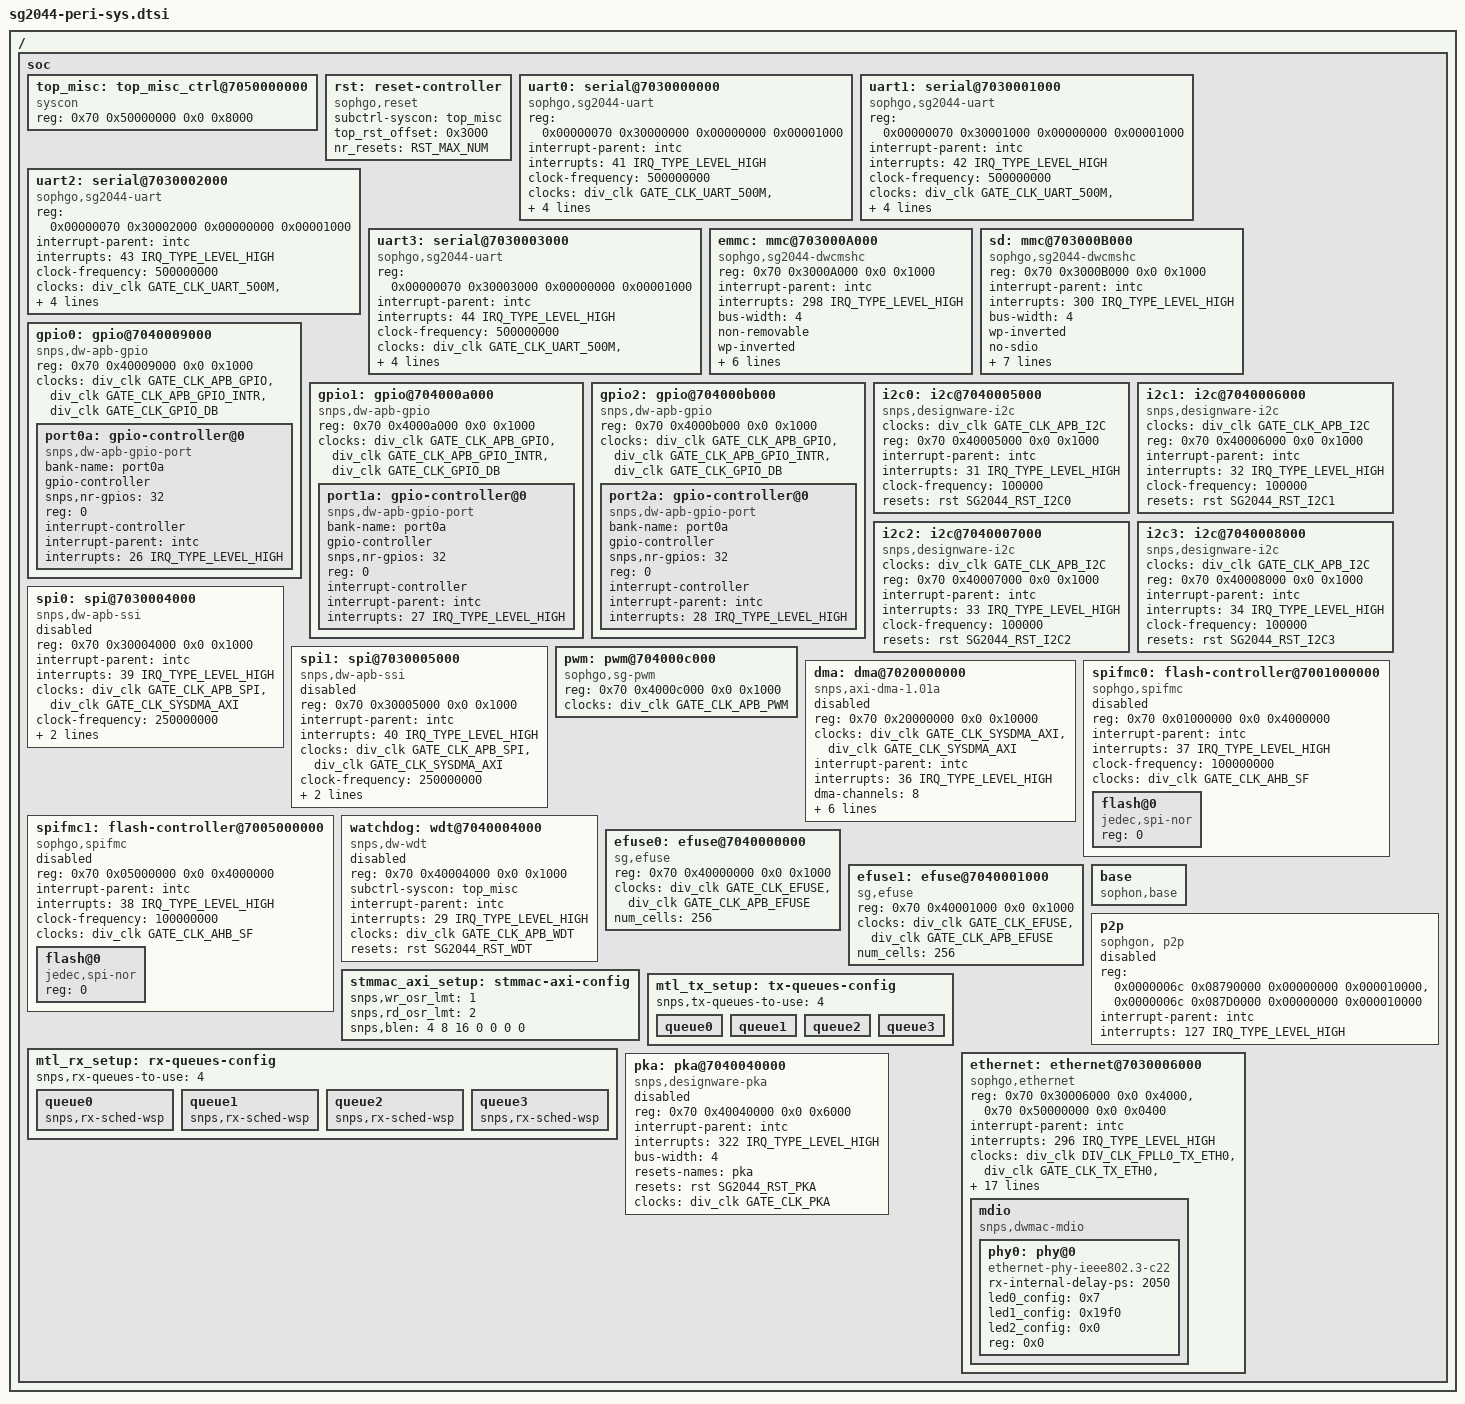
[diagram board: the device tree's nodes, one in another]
// SPDX-License-Identifier: (GPL-2.0 OR MIT)
/*
 * Copyright (C) 2022 Sophgo Technology Inc. All rights reserved.
 */

/ {
	soc {
		top_misc: top_misc_ctrl@7050000000 {
			compatible = "syscon";
			reg = <0x70 0x50000000 0x0 0x8000>;
		};

		rst: reset-controller {
			#reset-cells = <1>;
			compatible = "sophgo,reset";
			subctrl-syscon = <&top_misc>;
			top_rst_offset = <0x3000>;
			nr_resets = <RST_MAX_NUM>;
		};

		uart0: serial@7030000000 {
			compatible = "sophgo,sg2044-uart", "snps,dw-apb-uart";
			reg = <0x00000070 0x30000000 0x00000000 0x00001000>;
			interrupt-parent = <&intc>;
			interrupts = <41 IRQ_TYPE_LEVEL_HIGH>;
			clock-frequency = <500000000>;
			clocks = <&div_clk GATE_CLK_UART_500M>,
				<&div_clk GATE_CLK_APB_UART>;
			clock-names = "baudclk", "apb_pclk";
			current-speed = <115200>;
			reg-shift = <2>;
			reg-io-width = <4>;
		};

		uart1: serial@7030001000 {
			compatible = "sophgo,sg2044-uart", "snps,dw-apb-uart";
			reg = <0x00000070 0x30001000 0x00000000 0x00001000>;
			interrupt-parent = <&intc>;
			interrupts = <42 IRQ_TYPE_LEVEL_HIGH>;
			clock-frequency = <500000000>;
			clocks = <&div_clk GATE_CLK_UART_500M>,
				<&div_clk GATE_CLK_APB_UART>;
			clock-names = "baudclk", "apb_pclk";
			current-speed = <115200>;
			reg-shift = <2>;
			reg-io-width = <4>;
		};

		uart2: serial@7030002000 {
			compatible = "sophgo,sg2044-uart", "snps,dw-apb-uart";
			reg = <0x00000070 0x30002000 0x00000000 0x00001000>;
			interrupt-parent = <&intc>;
			interrupts = <43 IRQ_TYPE_LEVEL_HIGH>;
			clock-frequency = <500000000>;
			clocks = <&div_clk GATE_CLK_UART_500M>,
				<&div_clk GATE_CLK_APB_UART>;
			clock-names = "baudclk", "apb_pclk";
			current-speed = <115200>;
			reg-shift = <2>;
			reg-io-width = <4>;
		};

		uart3: serial@7030003000 {
			compatible = "sophgo,sg2044-uart", "snps,dw-apb-uart";
			reg = <0x00000070 0x30003000 0x00000000 0x00001000>;
			interrupt-parent = <&intc>;
			interrupts = <44 IRQ_TYPE_LEVEL_HIGH>;
			clock-frequency = <500000000>;
			clocks = <&div_clk GATE_CLK_UART_500M>,
				<&div_clk GATE_CLK_APB_UART>;
			clock-names = "baudclk", "apb_pclk";
			current-speed = <115200>;
			reg-shift = <2>;
			reg-io-width = <4>;
		};

		emmc: mmc@703000A000 {
			compatible = "sophgo,sg2044-dwcmshc", "sophgo,sg2042-dwcmshc";
			reg = <0x70 0x3000A000 0x0 0x1000>;
			reg-names = "core_mem";
			interrupt-parent = <&intc>;
			interrupts = <298 IRQ_TYPE_LEVEL_HIGH>;
			bus-width = <4>;
			non-removable;
			wp-inverted;
			no-sdio;
			no-sd;
			resets = <&rst SG2044_RST_EMMC>;
			reset-names = "emmc";
			clocks =
			<&div_clk GATE_CLK_EMMC>,
			<&div_clk GATE_CLK_AXI_EMMC>,
			<&div_clk GATE_CLK_100K_EMMC>;
			clock-names = "core", "bus", "timer";
		};

		sd: mmc@703000B000 {
			compatible = "sophgo,sg2044-dwcmshc", "sophgo,sg2042-dwcmshc";
			reg = <0x70 0x3000B000 0x0 0x1000>;
			reg-names = "core_mem";
			interrupt-parent = <&intc>;
			interrupts = <300 IRQ_TYPE_LEVEL_HIGH>;
			bus-width = <4>;
			wp-inverted;
			no-sdio;
			no-mmc;
			no-1-8-v;
			switch-voltage-gpio = <&port0a 27 0>;
			resets = <&rst SG2044_RST_SD>;
			reset-names = "sdio";
			clocks =
			<&div_clk GATE_CLK_SD>,
			<&div_clk GATE_CLK_AXI_SD>,
			<&div_clk GATE_CLK_100K_SD>;
			clock-names = "core", "bus", "timer";
		};

		gpio0: gpio@7040009000 {
			compatible = "snps,dw-apb-gpio";
			reg = <0x70 0x40009000 0x0 0x1000>;
			#address-cells = <1>;
			#size-cells = <0>;
			clocks = <&div_clk GATE_CLK_APB_GPIO>,
					<&div_clk GATE_CLK_APB_GPIO_INTR>,
					<&div_clk GATE_CLK_GPIO_DB>;
			clock-names = "base_clk", "intr_clk", "db_clk";

			port0a: gpio-controller@0 {
				compatible = "snps,dw-apb-gpio-port";
				bank-name = "port0a";
				gpio-controller;
				#gpio-cells = <2>;
				snps,nr-gpios = <32>;
				reg = <0>;
				interrupt-controller;
				#interrupt-cells = <2>;
				interrupt-parent = <&intc>;
				interrupts = <26 IRQ_TYPE_LEVEL_HIGH>;
			};
		};

		gpio1: gpio@704000a000 {
			compatible = "snps,dw-apb-gpio";
			reg = <0x70 0x4000a000 0x0 0x1000>;
			#address-cells = <1>;
			#size-cells = <0>;

			clocks = <&div_clk GATE_CLK_APB_GPIO>,
					<&div_clk GATE_CLK_APB_GPIO_INTR>,
					<&div_clk GATE_CLK_GPIO_DB>;
			clock-names = "base_clk", "intr_clk", "db_clk";

			port1a: gpio-controller@0 {
				compatible = "snps,dw-apb-gpio-port";
				bank-name = "port0a";
				gpio-controller;
				#gpio-cells = <2>;
				snps,nr-gpios = <32>;
				reg = <0>;
				interrupt-controller;
				#interrupt-cells = <2>;
				interrupt-parent = <&intc>;
				interrupts = <27 IRQ_TYPE_LEVEL_HIGH>;
			};
		};

		gpio2: gpio@704000b000 {
			compatible = "snps,dw-apb-gpio";
			reg = <0x70 0x4000b000 0x0 0x1000>;
			#address-cells = <1>;
			#size-cells = <0>;
			clocks = <&div_clk GATE_CLK_APB_GPIO>,
					<&div_clk GATE_CLK_APB_GPIO_INTR>,
					<&div_clk GATE_CLK_GPIO_DB>;
			clock-names = "base_clk", "intr_clk", "db_clk";

			port2a: gpio-controller@0 {
				compatible = "snps,dw-apb-gpio-port";
				bank-name = "port0a";
				gpio-controller;
				#gpio-cells = <2>;
				snps,nr-gpios = <32>;
				reg = <0>;
				interrupt-controller;
				#interrupt-cells = <2>;
				interrupt-parent = <&intc>;
				interrupts = <28 IRQ_TYPE_LEVEL_HIGH>;
			};
		};

		i2c0: i2c@7040005000 {
			#address-cells = <1>;
			#size-cells = <0>;
			compatible = "snps,designware-i2c";
			clocks = <&div_clk GATE_CLK_APB_I2C>;
			clock-names = "clk_gate_apb_i2c";
			reg = <0x70 0x40005000 0x0 0x1000>;
			interrupt-parent = <&intc>;
			interrupts = <31 IRQ_TYPE_LEVEL_HIGH>;
			clock-frequency = <100000>;
			resets = <&rst SG2044_RST_I2C0>;
			reset-names = "i2c0";
		};

		i2c1: i2c@7040006000 {
			#address-cells = <1>;
			#size-cells = <0>;
			compatible = "snps,designware-i2c";
			clocks = <&div_clk GATE_CLK_APB_I2C>;
			clock-names = "clk_gate_apb_i2c";
			reg = <0x70 0x40006000 0x0 0x1000>;
			interrupt-parent = <&intc>;
			interrupts = <32 IRQ_TYPE_LEVEL_HIGH>;
			clock-frequency = <100000>;
			resets = <&rst SG2044_RST_I2C1>;
			reset-names = "i2c1";
		};

		i2c2: i2c@7040007000 {
			#address-cells = <1>;
			#size-cells = <0>;
			compatible = "snps,designware-i2c";
			clocks = <&div_clk GATE_CLK_APB_I2C>;
			clock-names = "clk_gate_apb_i2c";
			reg = <0x70 0x40007000 0x0 0x1000>;
			interrupt-parent = <&intc>;
			interrupts = <33 IRQ_TYPE_LEVEL_HIGH>;
			clock-frequency = <100000>;
			resets = <&rst SG2044_RST_I2C2>;
			reset-names = "i2c2";
		};

		i2c3: i2c@7040008000 {
			#address-cells = <1>;
			#size-cells = <0>;
			compatible = "snps,designware-i2c";
			clocks = <&div_clk GATE_CLK_APB_I2C>;
			clock-names = "clk_gate_apb_i2c";
			reg = <0x70 0x40008000 0x0 0x1000>;
			interrupt-parent = <&intc>;
			interrupts = <34 IRQ_TYPE_LEVEL_HIGH>;
			clock-frequency = <100000>;
			resets = <&rst SG2044_RST_I2C3>;
			reset-names = "i2c3";
		};

		spi0: spi@7030004000 {
			compatible = "snps,dw-apb-ssi";
			#address-cells = <1>;
			#size-cells = <0>;
			reg = <0x70 0x30004000 0x0 0x1000>;
			interrupt-parent = <&intc>;
			interrupts = <39 IRQ_TYPE_LEVEL_HIGH>;
			clocks = <&div_clk GATE_CLK_APB_SPI>,
				<&div_clk GATE_CLK_SYSDMA_AXI>;
			clock-frequency = <250000000>;
			resets = <&rst SG2044_RST_SPI0>;
			reset-names = "spi";
			num-cs = <2>;
			status = "disable";
		};

		spi1: spi@7030005000 {
			compatible = "snps,dw-apb-ssi";
			#address-cells = <1>;
			#size-cells = <0>;
			reg = <0x70 0x30005000 0x0 0x1000>;
			interrupt-parent = <&intc>;
			interrupts = <40 IRQ_TYPE_LEVEL_HIGH>;
			clocks = <&div_clk GATE_CLK_APB_SPI>,
				<&div_clk GATE_CLK_SYSDMA_AXI>;
			clock-frequency = <250000000>;
			resets = <&rst SG2044_RST_SPI1>;
			reset-names = "spi";
			num-cs = <2>;
			status = "disable";
		};

		pwm: pwm@704000c000 {
			compatible = "sophgo,sg-pwm";
			reg = <0x70 0x4000c000 0x0 0x1000>;
			clocks = <&div_clk GATE_CLK_APB_PWM>;
			#pwm-cells = <2>;
		};

		dma: dma@7020000000 {
			compatible = "snps,axi-dma-1.01a";
			reg = <0x70 0x20000000 0x0 0x10000>;
			clock-names = "core-clk", "cfgr-clk";
			clocks = <&div_clk GATE_CLK_SYSDMA_AXI>,
				 <&div_clk GATE_CLK_SYSDMA_AXI>;
			interrupt-parent = <&intc>;
			interrupts = <36 IRQ_TYPE_LEVEL_HIGH>;
			dma-channels = <8>;
			#dma-cells = <1>;
			snps,priority = <0 1 2 3 4 5 6 7>;
			snps,block-size = <0x1000 0x1000 0x1000 0x1000
					   0x1000 0x1000 0x1000 0x1000>;
			snps,dma-masters = <2>;
			snps,data-width = <2>;
			snps,axi-max-burst-len = <4>;
			status = "disable";
		};

		spifmc0: flash-controller@7001000000 {
			compatible = "sophgo,spifmc";
			reg = <0x70 0x01000000 0x0 0x4000000>;
			reg-names = "memory";
			#address-cells = <1>;
			#size-cells = <0>;
			interrupt-parent = <&intc>;
			interrupts = <37 IRQ_TYPE_LEVEL_HIGH>;
			clock-frequency = <100000000>;
			clocks = <&div_clk GATE_CLK_AHB_SF>;
			status = "disable";
			flash@0 {
				reg = <0>;
				compatible = "jedec,spi-nor";
			};
		};

		spifmc1: flash-controller@7005000000 {
			compatible = "sophgo,spifmc";
			reg = <0x70 0x05000000 0x0 0x4000000>;
			reg-names = "memory";
			#address-cells = <1>;
			#size-cells = <0>;
			interrupt-parent = <&intc>;
			interrupts = <38 IRQ_TYPE_LEVEL_HIGH>;
			clock-frequency = <100000000>;
			clocks = <&div_clk GATE_CLK_AHB_SF>;
			status = "disable";
			flash@0 {
				reg = <0>;
				compatible = "jedec,spi-nor";
			};
		};

		watchdog: wdt@7040004000 {
			compatible = "snps,dw-wdt";
			reg = <0x70 0x40004000 0x0 0x1000>;
			subctrl-syscon = <&top_misc>;
			interrupt-parent = <&intc>;
			interrupts = <29 IRQ_TYPE_LEVEL_HIGH>;
			clocks = <&div_clk GATE_CLK_APB_WDT>;
			resets = <&rst SG2044_RST_WDT>;
			status = "disable";
		};

		efuse0: efuse@7040000000 {
			compatible = "sg,efuse";
			reg = <0x70 0x40000000 0x0 0x1000>;
			clock-names = "base_clk", "apb_clk";
			clocks = <&div_clk GATE_CLK_EFUSE>,
				 <&div_clk GATE_CLK_APB_EFUSE>;
			num_cells = <256>;
		};

		efuse1: efuse@7040001000 {
			compatible = "sg,efuse";
			reg = <0x70 0x40001000 0x0 0x1000>;
			clock-names = "base_clk", "apb_clk";
			clocks = <&div_clk GATE_CLK_EFUSE>,
				 <&div_clk GATE_CLK_APB_EFUSE>;
			num_cells = <256>;
		};

		base: base {
			compatible = "sophon,base";
		};

		p2p: p2p {
			compatible = "sophgon, p2p";
			reg = <0x0000006c 0x08790000 0x00000000 0x000010000>,
				<0x0000006c 0x087D0000 0x00000000 0x000010000>;
			reg-names = "cdma_cfg","cxp_top_cfg";
			interrupt-parent = <&intc>;
			interrupts = <127 IRQ_TYPE_LEVEL_HIGH>;
			interrupt-names = "CXP_CDMA0";
			status = "disabled";
		};

		stmmac_axi_setup: stmmac-axi-config {
			snps,wr_osr_lmt = <1>;
			snps,rd_osr_lmt = <2>;
			snps,blen = <4 8 16 0 0 0 0>;
		};

		mtl_rx_setup: rx-queues-config {
			snps,rx-queues-to-use = <4>;
			queue0 {snps,rx-sched-wsp;};
			queue1 {snps,rx-sched-wsp;};
			queue2 {snps,rx-sched-wsp;};
			queue3 {snps,rx-sched-wsp;};
		};

		mtl_tx_setup: tx-queues-config {
			snps,tx-queues-to-use = <4>;
			queue0 {};
			queue1 {};
			queue2 {};
			queue3 {};
		};

		ethernet: ethernet@7030006000 {
			compatible = "sophgo,ethernet";
			reg = <0x70 0x30006000 0x0 0x4000>,
				<0x70 0x50000000 0x0 0x0400>;
			interrupt-names = "macirq";
			interrupt-parent = <&intc>;
			interrupts = <296 IRQ_TYPE_LEVEL_HIGH>;
			clock-names = "clk_tx", "gate_clk_tx", "stmmaceth", "ptp_ref", "gate_clk_ref";
			clocks = <&div_clk DIV_CLK_FPLL0_TX_ETH0>,
				<&div_clk GATE_CLK_TX_ETH0>,
				<&div_clk GATE_CLK_AXI_ETH0>,
				<&div_clk DIV_CLK_FPLL0_PTP_REF_I_ETH0>,
				<&div_clk GATE_CLK_REF_ETH0>;
			/* no hash filter and perfect filter support */
			snps,multicast-filter-bins = <0>;
			snps,perfect-filter-entries = <1>;

			snps,txpbl = <32>;
			snps,rxpbl = <32>;
			snps,aal;
			snps,tso;

			snps,axi-config = <&stmmac_axi_setup>;
			snps,mtl-rx-config = <&mtl_rx_setup>;
			snps,mtl-tx-config = <&mtl_tx_setup>;

			sophgo,gmac;
			/*gmac defaults to disabling txdelay and enabling rxdelay */
			sophgo,gmac-no-rxdelay;

			/* enable phy rx delay and tx delay */
			phy-mode = "rgmii-id";
			phy-reset-gpios = <&port0a 28 0>;
			phy-handle = <&phy0>;

			mdio {
				#address-cells = <0x1>;
				#size-cells = <0x0>;
				compatible = "snps,dwmac-mdio";
				phy0: phy@0 {
					compatible = "ethernet-phy-ieee802.3-c22";
					device_type = "ethernet-phy";
					rx-internal-delay-ps = <2050>;
					led0_config = <0x7>;
					led1_config = <0x19f0>;
					led2_config = <0x0>;
					reg = <0x0>;
				};
			};

		};

        // pka device, change size from 0x1000 to 0x6000
        pka: pka@7040040000 {
            compatible = "snps,designware-pka";
            reg = <0x70 0x40040000 0x0 0x6000>;
            interrupt-parent = <&intc>;
            interrupts = <322 IRQ_TYPE_LEVEL_HIGH>;
            bus-width = <4>;
            resets-names = "pka";
            resets = <&rst SG2044_RST_PKA>;
            clock-names = "pka";
            clocks = <&div_clk GATE_CLK_PKA>;
            status = "disabled";
        };

	#if 0
		xlgmac_axi_setup: xlgmac-axi-config {
			snps,wr_osr_lmt = <63>;
			snps,rd_osr_lmt = <3>;
			snps,blen = <4 8 16 32 64 128 256>;
		};

		xlg_mtl_rx_setup: xlg-rx-queues-config {
			snps,rx-queues-to-use = <8>;
			queue0 {snps,rx-sched-wsp;};
			queue1 {snps,rx-sched-wsp;};
			queue2 {snps,rx-sched-wsp;};
			queue3 {snps,rx-sched-wsp;};
			queue4 {snps,rx-sched-wsp;};
			queue5 {snps,rx-sched-wsp;};
			queue6 {snps,rx-sched-wsp;};
			queue7 {snps,rx-sched-wsp;};
		};

		xlg_mtl_tx_setup: xlg-tx-queues-config {
			snps,tx-queues-to-use = <8>;
			queue0 {};
			queue1 {};
			queue2 {};
			queue3 {};
			queue4 {};
			queue5 {};
			queue6 {};
			queue7 {};
		};

		dwcxlg0: dwcxlg@6c08000000 {
			compatible = "sophgo,ethernet";
			reg = <0x6c 0x08000000 0x0 0x40000>;
			clock-names = "clk_gate_cxp_mac", "clk_gate_cxp_cfg";
			clocks = <&div_clk GATE_CLK_CXP_MAC>,
				<&div_clk GATE_CLK_CXP_CFG>;
			interrupt-parent = <&intc>;
			#if 0
			interrupts = <92 IRQ_TYPE_LEVEL_HIGH
					93 IRQ_TYPE_LEVEL_HIGH 94 IRQ_TYPE_LEVEL_HIGH
					95 IRQ_TYPE_LEVEL_HIGH 96 IRQ_TYPE_LEVEL_HIGH
					97 IRQ_TYPE_LEVEL_HIGH 98 IRQ_TYPE_LEVEL_HIGH
					99 IRQ_TYPE_LEVEL_HIGH 100 IRQ_TYPE_LEVEL_HIGH
					109 IRQ_TYPE_LEVEL_HIGH 110 IRQ_TYPE_LEVEL_HIGH
					111 IRQ_TYPE_LEVEL_HIGH 112 IRQ_TYPE_LEVEL_HIGH
					113 IRQ_TYPE_LEVEL_HIGH 114 IRQ_TYPE_LEVEL_HIGH
					115 IRQ_TYPE_LEVEL_HIGH 116 IRQ_TYPE_LEVEL_HIGH>;
			interrupt-names = "macirq", "tx_ch0", "tx_ch1", "tx_ch2", "tx_ch3",
						"tx_ch4", "tx_ch5", "tx_ch6", "tx_ch7",
						"rx_ch0", "rx_ch1", "rx_ch2", "rx_ch3",
						"rx_ch4", "rx_ch5", "rx_ch6", "rx_ch7";
			snps,multi_msi_en;
			#else
			interrupts = <92 IRQ_TYPE_LEVEL_HIGH>;
			interrupt-names = "macirq";
			#endif
			snps,tso;
			sophgo,xlgmac;
			snps,axi-config = <&xlgmac_axi_setup>;
			snps,mtl-rx-config = <&xlg_mtl_rx_setup>;
			snps,mtl-tx-config = <&xlg_mtl_tx_setup>;

			phy-mode = "xlgmii";
			fixed-link {
				speed = <100000>;
				full-duplex;
			};
		};
	#endif
	};
};
